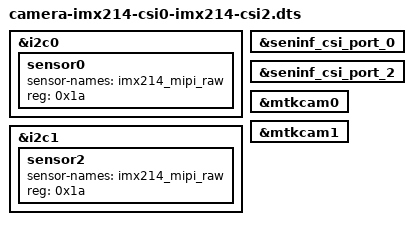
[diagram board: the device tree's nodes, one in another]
// SPDX-License-Identifier: GPL-2.0
/*
 * Copyright (c) 2024 MediaTek Inc.
 *
 */

/dts-v1/;
/plugin/;

#include "camera-common.dtsi"

/ {
	fragment@11 {
		target = <&i2c0>;
		__overlay__ {
			sensor0 {
				sensor-names = "imx214_mipi_raw";
				reg = <0x1a>;
				status = "okay";
			};
		};
	};

	fragment@12 {
		target = <&i2c1>;
		__overlay__ {
			sensor2 {
				sensor-names = "imx214_mipi_raw";
				reg = <0x1a>;
				status = "okay";
			};
		};
	};

	fragment@13 {
		target = <&seninf_csi_port_0>;
		__overlay__ {
			status = "okay";
		};
	};

	fragment@14 {
		target = <&seninf_csi_port_2>;
		__overlay__ {
			status = "okay";
		};
	};

	fragment@15 {
		target = <&mtkcam0>;
		__overlay__ {
			status = "okay";
		};
	};

	fragment@16 {
		target = <&mtkcam1>;
		__overlay__ {
			status = "okay";
		};
	};
};
